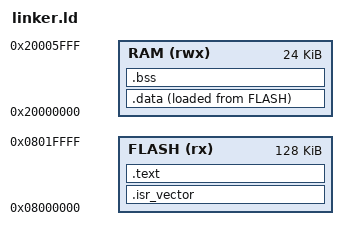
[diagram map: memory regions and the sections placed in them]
MEMORY
{
    FLASH (rx)  : ORIGIN = 0x08000000, LENGTH = 128K
    RAM   (rwx) : ORIGIN = 0x20000000, LENGTH = 24K
}

_estack = ORIGIN(RAM) + LENGTH(RAM);

SECTIONS
{
    .isr_vector :
    {
        KEEP(*(.isr_vector))
    } > FLASH

    .text :
    {
        *(.text*)
        *(.rodata*)
    } > FLASH

    _sidata = LOADADDR(.data);

    .data :
    {
        . = ALIGN(4);
        _sdata = .;
        *(.data*)
        _edata = .;
    } > RAM AT > FLASH

    .bss :
    {
        . = ALIGN(4);
        _sbss = .;
        *(.bss*)
        *(COMMON)
        _ebss = .;
    } > RAM
}
